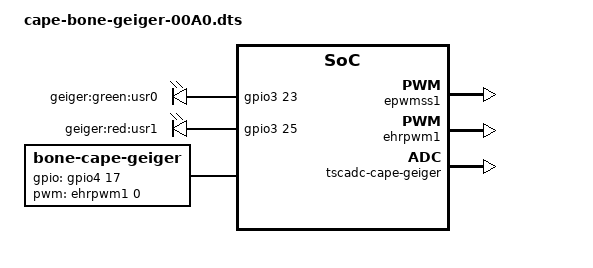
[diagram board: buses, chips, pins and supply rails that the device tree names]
/*
 * Copyright (C) 2012 Pantelis Antoniou <panto@antoniou-consulting.com>
 *
 * This program is free software; you can redistribute it and/or modify
 * it under the terms of the GNU General Public License version 2 as
 * published by the Free Software Foundation.
 */
/dts-v1/;
/plugin/;

/ {
	compatible = "ti,beaglebone", "ti,beaglebone-black";

	/* identification */
	part-number = "BB-BONE-GEIGER";
	version = "00A0";

	fragment@0 {
		target = <&am33xx_pinmux>;
		__overlay__ {

			bone_geiger_cape_led_pins: pinmux_bone_geiger_cape_led_pins {
				pinctrl-single,pins = <
					0xe4 0x07	/* lcd_hsync.gpio2_23, OUTPUT | MODE7 */
					0xec 0x07	/* lcd_ac_bias_en.gpio2_25, OUTPUT | MODE7 */
				>;
			};

			bone_geiger_cape_pins: pinmux_bone_geiger_cape_pins {
				pinctrl-single,pins = <
					0x48 0x06       /* gpmc_a2.ehrpwm1a, OMAP_MUX_MODE6 | AM33XX_PIN_OUTPUT */
					/* 0x19c 0x34 */	/* mcasp0_ahclkr.eCAP2_in_PWM2_out, OMAP_MUX_MODE4 | INPUT_PULLUP */
					0x19c 0x37 	/* mcasp0_ahclkr.gpio3_17, OMAP_MUX_MODE4 | INPUT_PULLUP */
				>;
			};
		};
	};

	fragment@2 {
		target = <&epwmss1>;
		__overlay__ {
			status = "okay";
		};
	};

	fragment@1 {
		target = <&ehrpwm1>;
		__overlay__ {
			status = "okay";
		};
	};

	fragment@3 {
		target = <&ocp>;
		__overlay__ {

			gpio-leds-cape-geiger {
				compatible = "gpio-leds";
				pinctrl-names = "default";
				pinctrl-0 = <&bone_geiger_cape_led_pins>;

				geiger-led0 {
					label = "geiger:green:usr0";
					gpios = <&gpio3 23 0>;
					linux,default-trigger = "geiger-run";
					default-state = "off";
				};

				geiger-led1 {
					label = "geiger:red:usr1";
					gpios = <&gpio3 25 0>;
					linux,default-trigger = "geiger-event";
					default-state = "off";
				};

			};

			tscadc-cape-geiger {
				compatible = "ti-tscadc-dt";
				adc-channels = <0 1 2 3 4 5 6 7>;
			};

			bone-cape-geiger {
				compatible = "bone-cape-geiger";
				status = "okay";

				pinctrl-names = "default";
				pinctrl-0 = <&bone_geiger_cape_pins>;

				pwms = <&ehrpwm1 0 500000 0>;
				pwm-names = "bone-geiger-cape";

				pwm-frequency  = <20000>;	/* 20KHz */
				pwm-duty-cycle = <60>;		/* 60% */

				event-blink-delay = <30>;	/* 30ms */

				gpios = <&gpio4 17 0>;		/* pulse */

				vsense-name = "AIN5";		/* analog vsense */
				vsense-scale = <37325>;		/* scaling */
			};
		};
	};
};
